VERSION ""

NS_ :

BS_:

BU_:

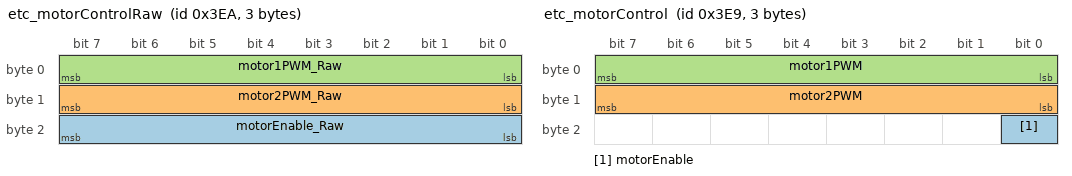
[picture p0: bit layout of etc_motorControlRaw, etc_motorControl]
BO_ 1002 etc_motorControlRaw: 3 Vector__XXX
 SG_ motorEnable_Raw : 16|8@1+ (1,0) [0|255] "bool" Vector__XXX
 SG_ motor2PWM_Raw : 8|8@1+ (1,0) [0|255] "%" Vector__XXX
 SG_ motor1PWM_Raw : 0|8@1+ (1,0) [0|255] "%" Vector__XXX

BO_ 1001 etc_motorControl: 3 Vector__XXX
 SG_ motorEnable : 16|1@1+ (1,0) [0|1] "bool" Vector__XXX
 SG_ motor2PWM : 8|8@1+ (1,0) [0|255] "%" Vector__XXX
 SG_ motor1PWM : 0|8@1+ (1,0) [0|255] "%" Vector__XXX

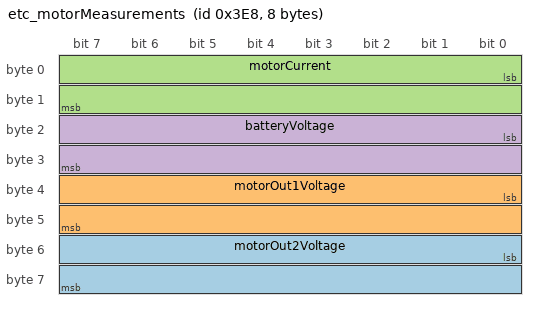
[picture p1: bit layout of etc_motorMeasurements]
BO_ 1000 etc_motorMeasurements: 8 Vector__XXX
 SG_ motorOut2Voltage : 48|16@1- (0.001,0) [-32.768|32.767] "V" Vector__XXX
 SG_ motorOut1Voltage : 32|16@1- (0.001,0) [-32.768|32.767] "V" Vector__XXX
 SG_ motorCurrent : 0|16@1- (0.001,0) [-32.768|32.767] "A" Vector__XXX
 SG_ batteryVoltage : 16|16@1- (0.001,0) [-32.768|32.767] "V" Vector__XXX
